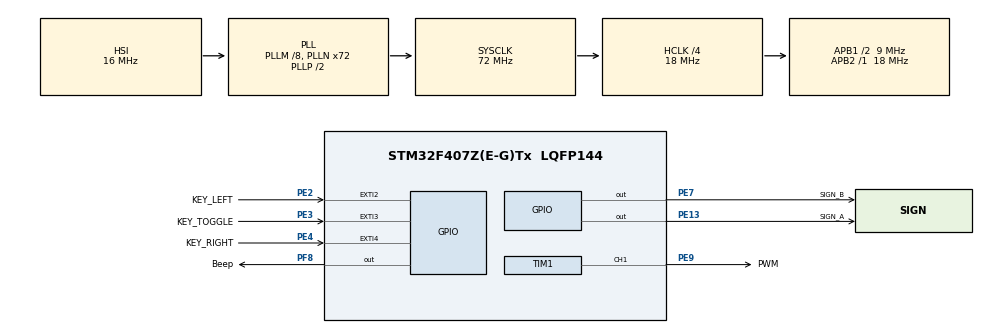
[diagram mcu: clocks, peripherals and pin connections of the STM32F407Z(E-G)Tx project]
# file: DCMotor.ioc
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Mcu.Family=STM32F4
Mcu.Name=STM32F407Z(E-G)Tx
Mcu.Package=LQFP144
NVIC.EXTI2_IRQn=true\:2\:0\:true\:false\:true\:true\:true\:true
NVIC.EXTI3_IRQn=true\:2\:0\:true\:false\:true\:true\:true\:true
NVIC.EXTI4_IRQn=true\:2\:0\:true\:false\:true\:true\:true\:true
NVIC.PriorityGroup=NVIC_PRIORITYGROUP_4
NVIC.TIM1_BRK_TIM9_IRQn=true\:3\:0\:true\:false\:true\:true\:true\:true
NVIC.TIM1_CC_IRQn=true\:3\:0\:true\:false\:true\:true\:true\:true
NVIC.TIM1_TRG_COM_TIM11_IRQn=true\:3\:0\:true\:false\:true\:true\:true\:true
NVIC.TIM1_UP_TIM10_IRQn=true\:3\:0\:true\:false\:true\:true\:true\:true
PC14-OSC32_IN.Mode=LSE-External-Clock-Source
PC14-OSC32_IN.Signal=RCC_OSC32_IN
PC15-OSC32_OUT.Mode=LSE-External-Clock-Source
PC15-OSC32_OUT.Signal=RCC_OSC32_OUT
PE13.GPIO_Label=SIGN_A
PE13.GPIO_Speed=GPIO_SPEED_FREQ_MEDIUM
PE13.Signal=GPIO_Output
PE2.GPIO_Label=KEY_LEFT
PE2.GPIO_ModeDefaultEXTI=GPIO_MODE_IT_FALLING
PE2.GPIO_PuPd=GPIO_PULLUP
PE2.Signal=GPXTI2
PE3.GPIO_Label=KEY_TOGGLE
PE3.GPIO_ModeDefaultEXTI=GPIO_MODE_IT_FALLING
PE3.GPIO_PuPd=GPIO_PULLUP
PE3.Signal=GPXTI3
PE4.GPIO_Label=KEY_RIGHT
PE4.GPIO_ModeDefaultEXTI=GPIO_MODE_IT_FALLING
PE4.GPIO_PuPd=GPIO_PULLUP
PE4.Signal=GPXTI4
PE7.GPIO_Label=SIGN_B
PE7.GPIO_Speed=GPIO_SPEED_FREQ_MEDIUM
PE7.Signal=GPIO_Output
PE9.GPIO_Label=PWM
PE9.Signal=S_TIM1_CH1
PF8.GPIO_Label=Beep
PF8.GPIO_Speed=GPIO_SPEED_FREQ_MEDIUM
PF8.Signal=GPIO_Output
PH0-OSC_IN.Mode=HSE-External-Clock-Source
PH0-OSC_IN.Signal=RCC_OSC_IN
PH1-OSC_OUT.Mode=HSE-External-Clock-Source
PH1-OSC_OUT.Signal=RCC_OSC_OUT
ProjectManager.HeapSize=0x200
ProjectManager.StackSize=0x400
ProjectManager.TargetToolchain=CMake
RCC.48MHZClocksFreq_Value=36000000
RCC.AHBCLKDivider=RCC_SYSCLK_DIV4
RCC.AHBFreq_Value=18000000
RCC.APB1CLKDivider=RCC_HCLK_DIV2
RCC.APB1Freq_Value=9000000
RCC.APB1TimFreq_Value=18000000
RCC.APB2Freq_Value=18000000
RCC.APB2TimFreq_Value=18000000
RCC.CortexFreq_Value=18000000
RCC.HCLKFreq_Value=18000000
RCC.HSE_VALUE=8000000
RCC.HSI_VALUE=16000000
RCC.LSE_VALUE=32768
RCC.PLLM=8
RCC.PLLN=72
RCC.SYSCLKFreq_VALUE=72000000
RCC.SYSCLKSource=RCC_SYSCLKSOURCE_PLLCLK
RCC.VCOOutputFreq_Value=144000000
SH.S_TIM1_CH1.0=TIM1_CH1,PWM Generation1 CH1
TIM1.Channel-PWM\ Generation1\ CH1=TIM_CHANNEL_1
TIM1.Period=1000-1
TIM1.Prescaler=0
board=custom

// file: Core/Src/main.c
/* USER CODE BEGIN Header */
/**
 ******************************************************************************
 * @file           : main.c
 * @brief          : Main program body
 ******************************************************************************
 * @attention
 *
 * Copyright (c) 2024 STMicroelectronics.
 * All rights reserved.
 *
 * This software is licensed under terms that can be found in the LICENSE file
 * in the root directory of this software component.
 * If no LICENSE file comes with this software, it is provided AS-IS.
 *
 ******************************************************************************
 */
/* USER CODE END Header */
#include "main.h"

/* USER CODE BEGIN Includes */
#include "dc_motor.h"
/* USER CODE END Includes */

TIM_HandleTypeDef htim1;

/* USER CODE BEGIN PV */
uint32_t speed = 0;
enum MOTOR_State motor_state = MOTOR_STOP;
/* USER CODE END PV */

void SystemClock_Config(void);
static void MX_GPIO_Init(void);
static void MX_TIM1_Init(void);

int main(void)
{

  /* MCU Configuration--------------------------------------------------------*/

  /* Reset of all peripherals, Initializes the Flash interface and the Systick. */
  HAL_Init();

  /* Configure the system clock */
  SystemClock_Config();

  /* Initialize all configured peripherals */
  MX_GPIO_Init();
  MX_TIM1_Init();
  /* USER CODE BEGIN 2 */
  HAL_TIM_PWM_Start(&htim1, TIM_CHANNEL_1);
  MOTOR_Stop();
  /* USER CODE END 2 */

  /* Infinite loop */
  while (1) {

  }
}

void SystemClock_Config(void)
{
  RCC_OscInitTypeDef RCC_OscInitStruct = {0};
  RCC_ClkInitTypeDef RCC_ClkInitStruct = {0};

  /** Configure the main internal regulator output voltage
  */
  __HAL_RCC_PWR_CLK_ENABLE();
  __HAL_PWR_VOLTAGESCALING_CONFIG(PWR_REGULATOR_VOLTAGE_SCALE1);

  /** Initializes the RCC Oscillators according to the specified parameters
  * in the RCC_OscInitTypeDef structure.
  */
  RCC_OscInitStruct.OscillatorType = RCC_OSCILLATORTYPE_HSI;
  RCC_OscInitStruct.HSIState = RCC_HSI_ON;
  RCC_OscInitStruct.HSICalibrationValue = RCC_HSICALIBRATION_DEFAULT;
  RCC_OscInitStruct.PLL.PLLState = RCC_PLL_ON;
  RCC_OscInitStruct.PLL.PLLSource = RCC_PLLSOURCE_HSI;
  RCC_OscInitStruct.PLL.PLLM = 8;
  RCC_OscInitStruct.PLL.PLLN = 72;
  RCC_OscInitStruct.PLL.PLLP = RCC_PLLP_DIV2;
  RCC_OscInitStruct.PLL.PLLQ = 4;
  if (HAL_RCC_OscConfig(&RCC_OscInitStruct) != HAL_OK)
  {
    Error_Handler();
  }

  /** Initializes the CPU, AHB and APB buses clocks
  */
  RCC_ClkInitStruct.ClockType = RCC_CLOCKTYPE_HCLK|RCC_CLOCKTYPE_SYSCLK
                              |RCC_CLOCKTYPE_PCLK1|RCC_CLOCKTYPE_PCLK2;
  RCC_ClkInitStruct.SYSCLKSource = RCC_SYSCLKSOURCE_PLLCLK;
  RCC_ClkInitStruct.AHBCLKDivider = RCC_SYSCLK_DIV4;
  RCC_ClkInitStruct.APB1CLKDivider = RCC_HCLK_DIV2;
  RCC_ClkInitStruct.APB2CLKDivider = RCC_HCLK_DIV1;

  if (HAL_RCC_ClockConfig(&RCC_ClkInitStruct, FLASH_LATENCY_0) != HAL_OK)
  {
    Error_Handler();
  }
}

static void MX_TIM1_Init(void)
{

  TIM_MasterConfigTypeDef sMasterConfig = {0};
  TIM_OC_InitTypeDef sConfigOC = {0};
  TIM_BreakDeadTimeConfigTypeDef sBreakDeadTimeConfig = {0};

  htim1.Instance = TIM1;
  htim1.Init.Prescaler = 0;
  htim1.Init.CounterMode = TIM_COUNTERMODE_UP;
  htim1.Init.Period = 1000-1;
  htim1.Init.ClockDivision = TIM_CLOCKDIVISION_DIV1;
  htim1.Init.RepetitionCounter = 0;
  htim1.Init.AutoReloadPreload = TIM_AUTORELOAD_PRELOAD_DISABLE;
  if (HAL_TIM_PWM_Init(&htim1) != HAL_OK)
  {
    Error_Handler();
  }
  sMasterConfig.MasterOutputTrigger = TIM_TRGO_RESET;
  sMasterConfig.MasterSlaveMode = TIM_MASTERSLAVEMODE_DISABLE;
  if (HAL_TIMEx_MasterConfigSynchronization(&htim1, &sMasterConfig) != HAL_OK)
  {
    Error_Handler();
  }
  sConfigOC.OCMode = TIM_OCMODE_PWM1;
  sConfigOC.Pulse = 0;
  sConfigOC.OCPolarity = TIM_OCPOLARITY_HIGH;
  sConfigOC.OCNPolarity = TIM_OCNPOLARITY_HIGH;
  sConfigOC.OCFastMode = TIM_OCFAST_DISABLE;
  sConfigOC.OCIdleState = TIM_OCIDLESTATE_RESET;
  sConfigOC.OCNIdleState = TIM_OCNIDLESTATE_RESET;
  if (HAL_TIM_PWM_ConfigChannel(&htim1, &sConfigOC, TIM_CHANNEL_1) != HAL_OK)
  {
    Error_Handler();
  }
  sBreakDeadTimeConfig.OffStateRunMode = TIM_OSSR_DISABLE;
  sBreakDeadTimeConfig.OffStateIDLEMode = TIM_OSSI_DISABLE;
  sBreakDeadTimeConfig.LockLevel = TIM_LOCKLEVEL_OFF;
  sBreakDeadTimeConfig.DeadTime = 0;
  sBreakDeadTimeConfig.BreakState = TIM_BREAK_DISABLE;
  sBreakDeadTimeConfig.BreakPolarity = TIM_BREAKPOLARITY_HIGH;
  sBreakDeadTimeConfig.AutomaticOutput = TIM_AUTOMATICOUTPUT_DISABLE;
  if (HAL_TIMEx_ConfigBreakDeadTime(&htim1, &sBreakDeadTimeConfig) != HAL_OK)
  {
    Error_Handler();
  }
  HAL_TIM_MspPostInit(&htim1);

}

static void MX_GPIO_Init(void)
{
  GPIO_InitTypeDef GPIO_InitStruct = {0};

  /* GPIO Ports Clock Enable */
  __HAL_RCC_GPIOE_CLK_ENABLE();
  __HAL_RCC_GPIOC_CLK_ENABLE();
  __HAL_RCC_GPIOF_CLK_ENABLE();
  __HAL_RCC_GPIOH_CLK_ENABLE();

  /*Configure GPIO pin Output Level */
  HAL_GPIO_WritePin(Beep_GPIO_Port, Beep_Pin, GPIO_PIN_RESET);

  /*Configure GPIO pin Output Level */
  HAL_GPIO_WritePin(GPIOE, SIGN_B_Pin|SIGN_A_Pin, GPIO_PIN_RESET);

  /*Configure GPIO pins : KEY_LEFT_Pin KEY_TOGGLE_Pin KEY_RIGHT_Pin */
  GPIO_InitStruct.Pin = KEY_LEFT_Pin|KEY_TOGGLE_Pin|KEY_RIGHT_Pin;
  GPIO_InitStruct.Mode = GPIO_MODE_IT_FALLING;
  GPIO_InitStruct.Pull = GPIO_PULLUP;
  HAL_GPIO_Init(GPIOE, &GPIO_InitStruct);

  /*Configure GPIO pin : Beep_Pin */
  GPIO_InitStruct.Pin = Beep_Pin;
  GPIO_InitStruct.Mode = GPIO_MODE_OUTPUT_PP;
  GPIO_InitStruct.Pull = GPIO_NOPULL;
  GPIO_InitStruct.Speed = GPIO_SPEED_FREQ_MEDIUM;
  HAL_GPIO_Init(Beep_GPIO_Port, &GPIO_InitStruct);

  /*Configure GPIO pins : SIGN_B_Pin SIGN_A_Pin */
  GPIO_InitStruct.Pin = SIGN_B_Pin|SIGN_A_Pin;
  GPIO_InitStruct.Mode = GPIO_MODE_OUTPUT_PP;
  GPIO_InitStruct.Pull = GPIO_NOPULL;
  GPIO_InitStruct.Speed = GPIO_SPEED_FREQ_MEDIUM;
  HAL_GPIO_Init(GPIOE, &GPIO_InitStruct);

  /* EXTI interrupt init*/
  HAL_NVIC_SetPriority(EXTI2_IRQn, 2, 0);
  HAL_NVIC_EnableIRQ(EXTI2_IRQn);

  HAL_NVIC_SetPriority(EXTI3_IRQn, 2, 0);
  HAL_NVIC_EnableIRQ(EXTI3_IRQn);

  HAL_NVIC_SetPriority(EXTI4_IRQn, 2, 0);
  HAL_NVIC_EnableIRQ(EXTI4_IRQn);

}

void Error_Handler(void)
{
  __disable_irq();
  while (1) {
  }
}

#ifdef  USE_FULL_ASSERT
/**
  * @brief  Reports the name of the source file and the source line number
  *         where the assert_param error has occurred.
  * @param  file: pointer to the source file name
  * @param  line: assert_param error line source number
  * @retval None
  */
void assert_failed(uint8_t *file, uint32_t line)
{
  /* USER CODE BEGIN 6 */
  /* User can add his own implementation to report the file name and line
     number, ex: printf("Wrong parameters value: file %s on line %d\r\n", file,
     line) */
  /* USER CODE END 6 */
}
#endif /* USE_FULL_ASSERT */
